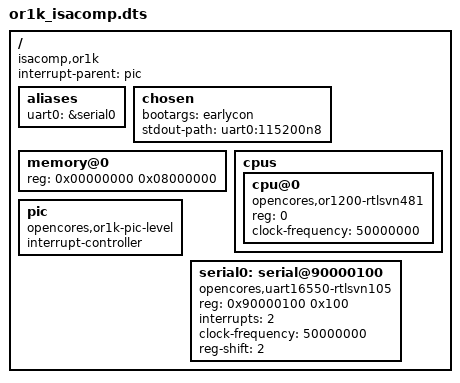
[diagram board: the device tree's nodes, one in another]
// SPDX-License-Identifier: GPL-2.0
/dts-v1/;
/ {
	compatible = "isacomp,or1k";
	#address-cells = <1>;
	#size-cells = <1>;
	interrupt-parent = <&pic>;

	aliases {
		uart0 = &serial0;
	};

	chosen {
		bootargs = "earlycon";
		stdout-path = "uart0:115200n8";
	};

	memory@0 {
		device_type = "memory";
		reg = <0x00000000 0x08000000>;  /* 128MB */
	};

	cpus {
		#address-cells = <1>;
		#size-cells = <0>;
		cpu@0 {
			device_type = "cpu";
			compatible = "opencores,or1200-rtlsvn481";
			reg = <0>;
			clock-frequency = <50000000>;
		};
	};

	/*
	 * OR1K PIC is built into CPU and accessed via special purpose
	 * registers.  It is not addressable and, hence, has no 'reg'
	 * property.
	 */
	pic: pic {
		compatible = "opencores,or1k-pic-level";
		#interrupt-cells = <1>;
		interrupt-controller;
	};

	/* Serial port - 8250/16550 compatible */
	serial0: serial@90000100 {
		compatible = "opencores,uart16550-rtlsvn105", "ns16550a";
		reg = <0x90000100 0x100>;
		interrupts = <2>;
		clock-frequency = <50000000>;
		reg-shift = <2>;
	};
};
